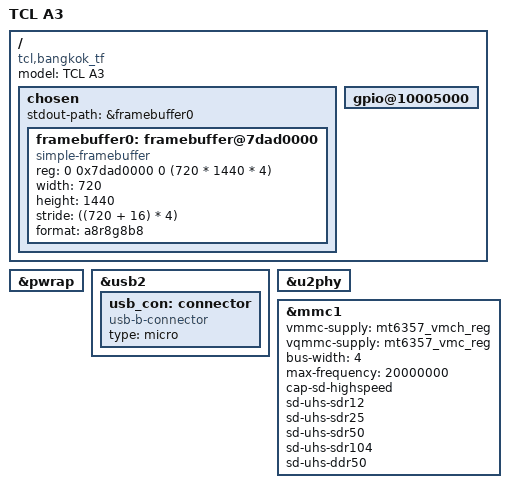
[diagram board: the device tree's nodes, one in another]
// SPDX-License-Identifier: (GPL-2.0 OR MIT)
/*
 * Device Tree Source for TCL A3 (bangkok_tf)
 *
 * Copyright (c) 2023 Arseniy Velikanov <adomerlee@gmail.com>
 * Copyright (C) 2023 Brandon Boese
 */

/dts-v1/;

#include "mt6765.dtsi"
#include "mt6765-bl-quirks.dtsi"
#include "mt6357.dtsi"

/ {
    model = "TCL A3";
    compatible = "tcl,bangkok_tf", "mediatek,mt6762", "mediatek,mt6765";

    chosen {
        stdout-path = &framebuffer0;

        /*
         * HACK: Use display framebuffer setup by the lk bootloader for simplefb
         * NOTE: only text is rendered on VT (TTY) as an unknown bit has to be flipped to disable
         *        image compression!
         */
        framebuffer0: framebuffer@7dad0000 {
            compatible = "simple-framebuffer";
            reg = <0 0x7dad0000 0 (720 * 1440 * 4)>;
            status = "okay";
            width = <720>;
            height = <1440>;
            stride = <((720 + 16) * 4)>;
            format = "a8r8g8b8";
        };
    };

    /* The following are required by stock bootloader to merge with minimal DTBO */
    gpio@10005000 {
        linux,phandle = <0xdead>;
        phandle = <0xdead>;
    };
    __symbols__ {
        gpio = "/gpio@10005000";
    };
};

&pwrap {
    status = "okay";
};

&usb2 {
    status = "okay";

    usb_con: connector {
        compatible = "usb-b-connector";
        type = "micro";
    };
};

&u2phy {
    status = "okay";
};

&mmc1 {
    status = "okay";

    vmmc-supply = <&mt6357_vmch_reg>;
    vqmmc-supply = <&mt6357_vmc_reg>;

    bus-width = <4>;
    max-frequency = <20000000>;
    cap-sd-highspeed;
    sd-uhs-sdr12;
    sd-uhs-sdr25;
    sd-uhs-sdr50;
    sd-uhs-sdr104;
    sd-uhs-ddr50;
};
